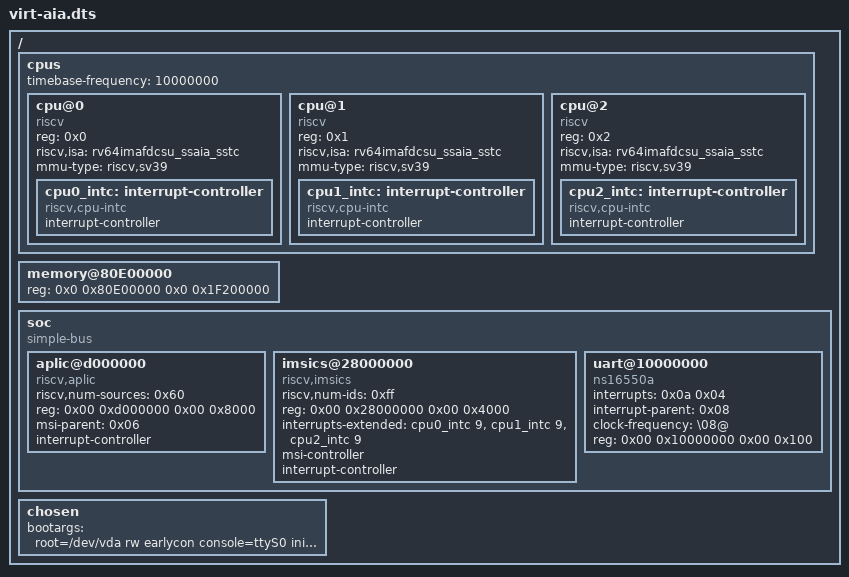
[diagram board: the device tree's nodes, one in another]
/dts-v1/;

/ {
	#address-cells = <0x2>;
	#size-cells = <0x2>;

	cpus {
		#address-cells = <0x1>;
		#size-cells = <0x0>;
		timebase-frequency = <10000000>;
		cpu@0 {
			device_type = "cpu";
			reg = <0x0>;
			status = "okay";
			compatible = "riscv";
			riscv,isa = "rv64imafdcsu_ssaia_sstc";
			mmu-type = "riscv,sv39";

			cpu0_intc: interrupt-controller {
				#interrupt-cells = <0x1>;
				interrupt-controller;
				compatible = "riscv,cpu-intc";
                phandle = <0x04>;
			};
		};
		cpu@1 {
			device_type = "cpu";
			reg = <0x1>;
			status = "okay";
			compatible = "riscv";
			riscv,isa = "rv64imafdcsu_ssaia_sstc";
			mmu-type = "riscv,sv39";

			cpu1_intc: interrupt-controller {
				#interrupt-cells = <0x1>;
				interrupt-controller;
				compatible = "riscv,cpu-intc";
			};
		};
		cpu@2 {
			device_type = "cpu";
			reg = <0x2>;
			status = "okay";
			compatible = "riscv";
			riscv,isa = "rv64imafdcsu_ssaia_sstc";
			mmu-type = "riscv,sv39";

			cpu2_intc: interrupt-controller {
				#interrupt-cells = <0x1>;
				interrupt-controller;
				compatible = "riscv,cpu-intc";
			};
		};
	};

	memory@80E00000 {
		device_type = "memory";
		reg = <0x0 0x80E00000 0x0 0x1F200000>;
	};

soc{
	#address-cells = <0x02>;
	#size-cells = <0x02>;
	compatible = "simple-bus";
	ranges;

	aplic@d000000 {
		phandle = <0x08>;
		riscv,num-sources = <0x60>;
		reg = <0x00 0xd000000 0x00 0x8000>;
		msi-parent = <0x06>;
		interrupt-controller;
		#interrupt-cells = <0x02>;
		compatible = "riscv,aplic";
	};

	imsics@28000000 {
		phandle = <0x06>;
		riscv,num-ids = <0xff>;
		reg = <0x00 0x28000000 0x00 0x4000>;
		interrupts-extended = <
			&cpu0_intc 9 
			&cpu1_intc 9 
			&cpu2_intc 9
		>;
		msi-controller;
		interrupt-controller;
		#interrupt-cells = <0x00>;
		compatible = "riscv,imsics";
	};

	uart@10000000 {
		interrupts = <0x0a 0x04>;
		interrupt-parent = <0x08>;
		clock-frequency = "\08@";
		reg = <0x00 0x10000000 0x00 0x100>;
		compatible = "ns16550a";
	};

    };
	chosen {
		bootargs = "root=/dev/vda rw earlycon console=ttyS0 init=/bin/bash";
	};

};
